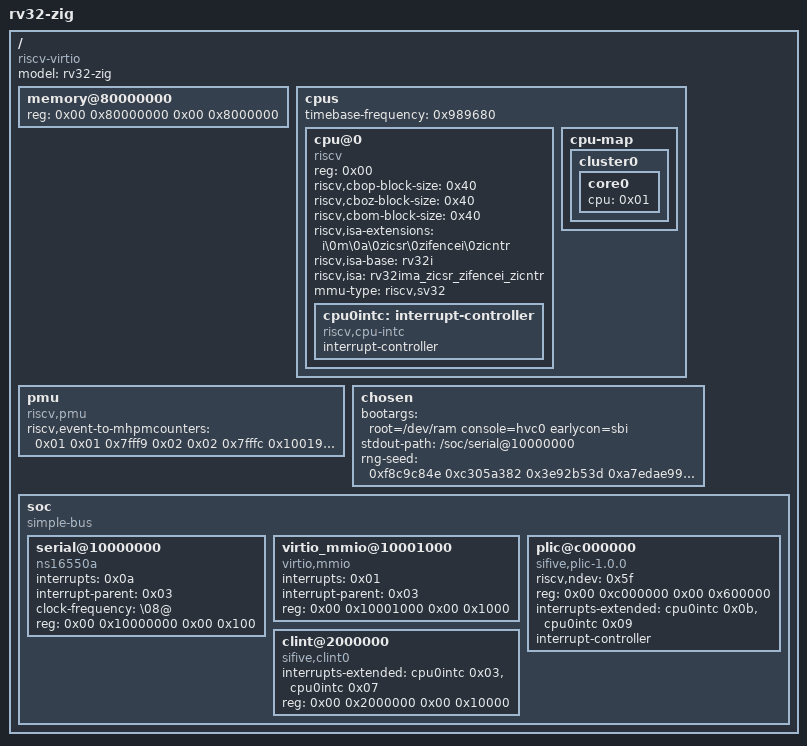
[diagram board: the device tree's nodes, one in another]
/dts-v1/;

/ {
	#address-cells = <0x02>;
	#size-cells = <0x02>;
	compatible = "riscv-virtio";
	model = "rv32-zig";

	memory@80000000 {
		device_type = "memory";
		reg = <0x00 0x80000000 0x00 0x8000000>; // 128KiB
	};

	cpus {
		#address-cells = <0x01>;
		#size-cells = <0x00>;
		timebase-frequency = <0x989680>;

		cpu@0 {
			phandle = <0x01>;
			device_type = "cpu";
			reg = <0x00>;
			status = "okay";
			compatible = "riscv";
			riscv,cbop-block-size = <0x40>;
			riscv,cboz-block-size = <0x40>;
			riscv,cbom-block-size = <0x40>;
			riscv,isa-extensions = "i\0m\0a\0zicsr\0zifencei\0zicntr";
			riscv,isa-base = "rv32i";
			riscv,isa = "rv32ima_zicsr_zifencei_zicntr";
			mmu-type = "riscv,sv32";

			cpu0intc: interrupt-controller {
				#interrupt-cells = <0x01>;
				interrupt-controller;
				compatible = "riscv,cpu-intc";
				phandle = <0x02>;
			};
		};

		cpu-map {

			cluster0 {

				core0 {
					cpu = <0x01>;
				};
			};
		};
	};

	pmu {
		riscv,event-to-mhpmcounters = <0x01 0x01 0x7fff9 0x02 0x02 0x7fffc 0x10019 0x10019 0x7fff8 0x1001b 0x1001b 0x7fff8 0x10021 0x10021 0x7fff8>;
		compatible = "riscv,pmu";
	};

	chosen {
        bootargs = "root=/dev/ram console=hvc0 earlycon=sbi";
		stdout-path = "/soc/serial@10000000";
		rng-seed = <0xf8c9c84e 0xc305a382 0x3e92b53d 0xa7edae99 0xaf7e128e 0xdf6fada3 0xff72947d 0x76be17c8>;
	};

	soc {
		#address-cells = <0x02>;
		#size-cells = <0x02>;
		compatible = "simple-bus";
		ranges;

		serial@10000000 {
			interrupts = <0x0a>;
			interrupt-parent = <0x03>;
			clock-frequency = "\08@";
			reg = <0x00 0x10000000 0x00 0x100>;
			compatible = "ns16550a";
		};

        virtio_mmio@10001000 {
			interrupts = <0x01>;
			interrupt-parent = <0x03>;
			reg = <0x00 0x10001000 0x00 0x1000>;
			compatible = "virtio,mmio";
		};

		plic@c000000 {
			phandle = <0x03>;
			riscv,ndev = <0x5f>;
			reg = <0x00 0xc000000 0x00 0x600000>;
            // corresponds to mei, sei
			interrupts-extended = <&cpu0intc 0x0b &cpu0intc 0x09>;
			interrupt-controller;
			compatible = "sifive,plic-1.0.0\0riscv,plic0";
			#address-cells = <0x00>;
			#interrupt-cells = <0x01>;
		};

		clint@2000000 {
            // corresponds to mti, sti
			interrupts-extended = <&cpu0intc 0x03 &cpu0intc 0x07>;
			reg = <0x00 0x2000000 0x00 0x10000>;
			compatible = "sifive,clint0\0riscv,clint0";
		};
	};
};
